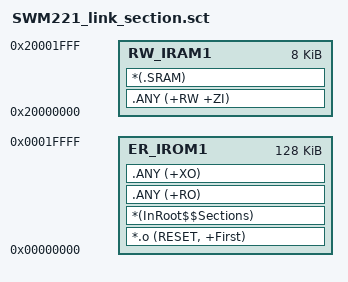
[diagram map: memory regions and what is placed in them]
; *************************************************************
; *** Scatter-Loading Description File generated by uVision ***
; *************************************************************

LR_IROM1 0x00000000 0x20000  {    ; load region size_region
  ER_IROM1 0x00000000 0x20000  {  ; load address = execution address
   *.o (RESET, +First)
   *(InRoot$$Sections)
   .ANY (+RO)
   .ANY (+XO)
  }
  RW_IRAM1 0x20000000 0x2000  {  ; RW data
   .ANY (+RW +ZI)
   *(.SRAM)
  }
}

;LR_SPIFLASH 0x70000000 0x01000000  {      ; load region size_region
;  REGION0 0x70000000 0x00400000  {
;    *(.SPIFLASH0)
;  }
;  REGION1 0x70400000 0x00400000  {
;    *(.SPIFLASH1)
;  }
;  REGION2 0x70800000 0x00400000  {
;    *(.SPIFLASH2)
;  }
;  REGION3 0x70C00000 0x00400000  {
;    *(.SPIFLASH3)
;  }
;}
